# EFR32MG27C230F768IM40 register map
Vendor: Silicon Labs; Series: EFR32; File version: B
Registers are 32-bit, read-write, reset 0x0 unless marked. A register's access mark holds for its fields unless they carry their own. Offsets are from the block's base; [hi:lo] are bit positions; {n}, {i} and the like mark numbered series; 'fields as' and 'values as' point back to an identical list.

## MSC_NS — MSC_NS Registers
Base 0x50030000
Same registers: MSC_S 0x40030000
0x00 IPVERSION ro reset 0x5
  [31:0] IPVERSION — IP Version ID
0x04 READCTRL reset 0x200000
  [21:20] MODE — Read Mode
    0=WS0 (Zero wait-states inserted in fetch or read transfers); 1=WS1 (One wait-state inserted for each fetch or read transfer. See Flash Wait-States table for details); 2=WS2 (Two wait-states inserted for eatch fetch or read transfer. See Flash Wait-States table for details); 3=WS3 (Three wait-states inserted for eatch fetch or read transfer. See Flash Wait-States table for details)
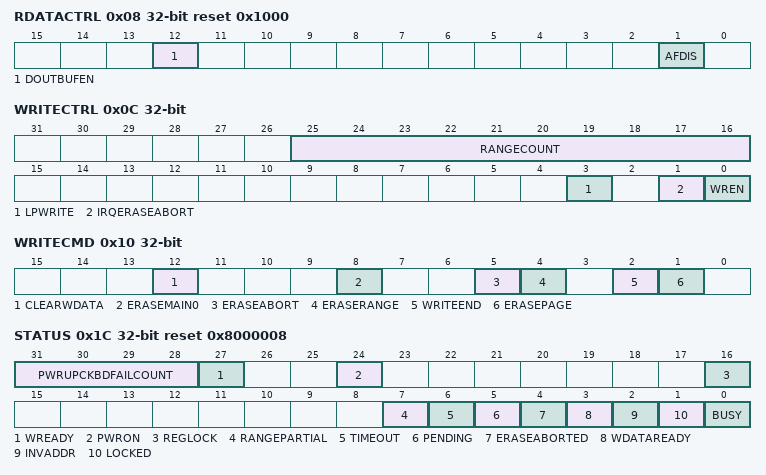
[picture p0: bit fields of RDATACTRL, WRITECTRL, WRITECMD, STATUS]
0x08 RDATACTRL reset 0x1000
  [12] DOUTBUFEN — Flash dout pipeline buffer enable
  [1] AFDIS — Automatic Invalidate Disable
0x0C WRITECTRL
  [25:16] RANGECOUNT — EraseRange Count
  [3] LPWRITE — Low-Power Write
  [1] IRQERASEABORT — Abort Page Erase on Interrupt
  [0] WREN — Enable Write/Erase Controller
0x10 WRITECMD wo
  [12] CLEARWDATA — Clear WDATA state
  [8] ERASEMAIN0 — Mass erase region 0
  [5] ERASEABORT — Abort erase sequence
  [4] ERASERANGE — Erase range of pages
  [2] WRITEEND — End Write Mode
  [1] ERASEPAGE
0x14 ADDRB
  [31:0] ADDRB — Page Erase or Write Address Buffer
0x18 WDATA
  [31:0] DATAW — Write Data
0x1C STATUS ro reset 0x8000008
  [31:28] PWRUPCKBDFAILCOUNT — Flash power up checkerboard pattern chec
  [27] WREADY — Flash Write Ready
  [24] PWRON — Flash Power On Status
  [16] REGLOCK — Register Lock Status
    0=UNLOCKED; 1=LOCKED
  [7] RANGEPARTIAL — EraseRange with skipped locked pages
  [6] TIMEOUT — Write Command Timeout
  [5] PENDING — Write Command In Queue
  [4] ERASEABORTED — Erase Operation Aborted
  [3] WDATAREADY — WDATA Write Ready
  [2] INVADDR — Invalid Write Address or Erase Page
  [1] LOCKED — Access Locked
  [0] BUSY — Erase/Write Busy
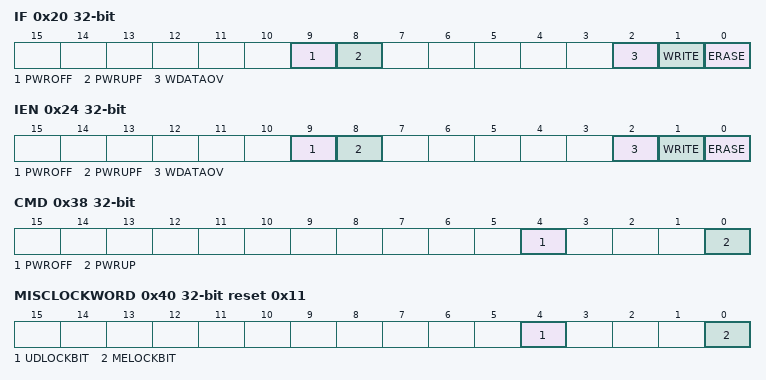
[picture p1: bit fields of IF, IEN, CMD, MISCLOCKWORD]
0x20 IF
  [9] PWROFF — Flash Power Off Sequence Complete Flag
  [8] PWRUPF — Flash Power Up Sequence Complete Flag
  [2] WDATAOV — Host write buffer overflow
  [1] WRITE — Host Write Done Interrupt Read Flag
  [0] ERASE — Host Erase Done Interrupt Read Flag
0x24 IEN
  [9] PWROFF — Flash Power Off Seq done irq enable
  [8] PWRUPF — Flash Power Up Seq done irq enable
  [2] WDATAOV — write data buffer overflow irq enable
  [1] WRITE — Write Done Interrupt enable
  [0] ERASE — Erase Done Interrupt enable
0x34 USERDATASIZE ro reset 0x4
  [5:0] USERDATASIZE
0x38 CMD wo
  [4] PWROFF — Flash power off/sleep command
  [0] PWRUP — Flash Power Up Command
0x3C LOCK wo
  [15:0] LOCKKEY — Configuration Lock
    0=LOCK; 0x1B71=UNLOCK
0x40 MISCLOCKWORD reset 0x11
  [4] UDLOCKBIT — User Data Lock
  [0] MELOCKBIT — Mass Erase Lock
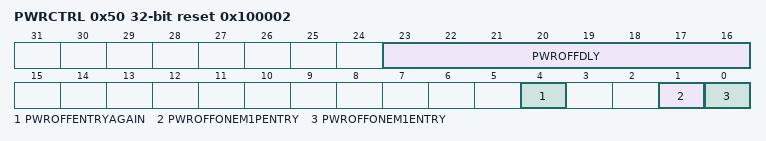
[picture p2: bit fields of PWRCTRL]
0x50 PWRCTRL reset 0x100002
  [23:16] PWROFFDLY — Power down delay
  [4] PWROFFENTRYAGAIN — POWER down flash again in EM1/EM1p
  [1] PWROFFONEM1PENTRY — Power down Flash macro when enter EM1P
  [0] PWROFFONEM1ENTRY — Power down Flash macro when enter EM1
{0x120+4i} PAGELOCK{i} (i=0..2)
  [31:0] LOCKBIT — page lock bit

## PDM_NS — PDM_NS Registers
Base 0x50098000
Same registers: PDM_S 0x40098000
0x00 IPVERSION ro
0x04 EN
  [0] EN — PDM enable
    0=DISABLE (Disable module); 1=ENABLE (Enable module)
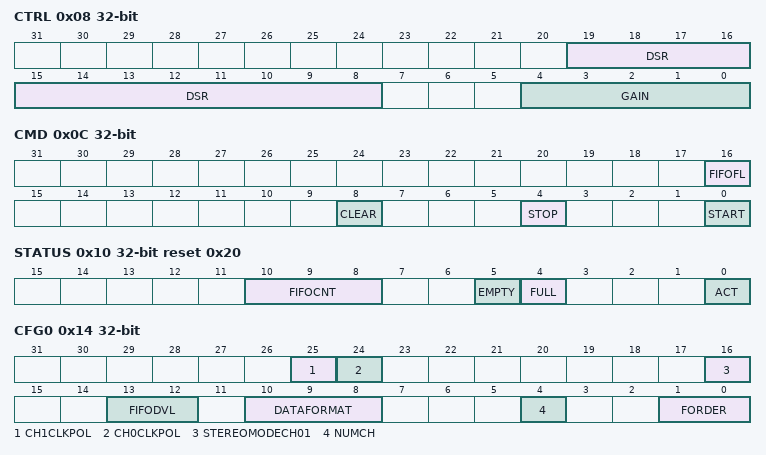
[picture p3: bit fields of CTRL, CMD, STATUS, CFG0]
0x08 CTRL
  [19:8] DSR — Down sampling rate of Decimation filter
  [4:0] GAIN — Selects Gain factor of DCF
0x0C CMD wo
  [16] FIFOFL — FIFO Flush
  [8] CLEAR — Clear DCF
  [4] STOP — Stop DCF
  [0] START — Start DCF
0x10 STATUS ro reset 0x20
  [10:8] FIFOCNT
  [5] EMPTY — FIFO EMPTY Status
  [4] FULL — FIFO FULL Status
  [0] ACT — PDM is active
0x14 CFG0
  [25] CH1CLKPOL — CH1 CLK Polarity
    0=NORMAL (Input data clocked on rising clock edge.); 1=INVERT (Input data clocked on falling clock edge.)
  [24] CH0CLKPOL — CH0 CLK Polarity
    values as CH1CLKPOL
  [16] STEREOMODECH01
    0=DISABLE (No Stereo mode.); 1=CH01ENABLE (CH0 and CH1 in Stereo mode.)
  [13:12] FIFODVL — Data Valid level in FIFO
    0=ONE (Atleast one word.); 1=TWO (Two words.); 2=THREE (Three words.); 3=FOUR (Four words.)
  [10:8] DATAFORMAT — Filter output format
    0=RIGHT16 (Right aligned 16-bit, left bits are sign extended.); 1=DOUBLE16 (Pack two 16-bit samples into one 32-bit word.); 2=RIGHT24 (Right aligned 24bit, left bits are sign extended.); 3=FULL32BIT (32 bit data.); 4=LEFT16 (Left aligned 16-bit, right bits are zeros.); 5=LEFT24 (Left aligned 24-bit, right bits are zeros.); 6=RAW32BIT (RAW 32 bit data from Integrator.)
  [4] NUMCH — Number of Channels
    0=ONE (One channel.); 1=TWO (Two channels.)
  [1:0] FORDER — Filter order
    0=SECOND (Second order filter.); 1=THIRD (Third order filter.); 2=FOURTH (Fourth order filter.); 3=FIFTH (Fifth order filter.)
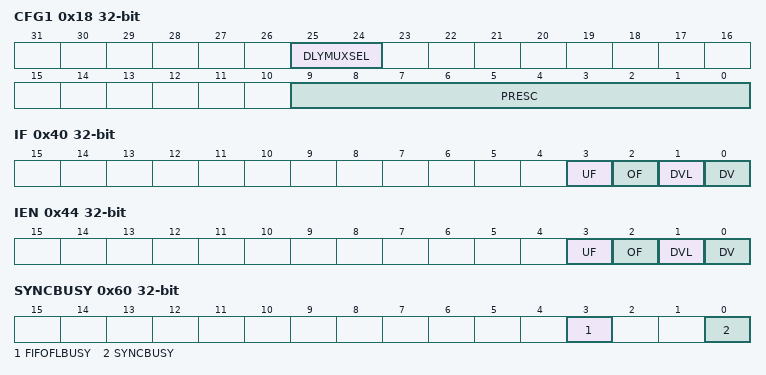
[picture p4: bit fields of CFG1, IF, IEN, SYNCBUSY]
0x18 CFG1
  [25:24] DLYMUXSEL — Data delay buffer mux selection
  [9:0] PRESC — Prescalar Setting for PDM sample
0x20 RXDATA ro
  [31:0] RXDATA — PDM received data
0x40 IF
  [3] UF — FIFO Undeflow Interrupt Flag
  [2] OF — FIFO Overflow Interrupt Flag
  [1] DVL — Data Valid Level Interrupt Flag
  [0] DV — Data Valid Interrupt Flag
0x44 IEN
  [3] UF — FIFO Undeflow Interrupt Enable
  [2] OF — FIFO Overflow Interrupt Enable
  [1] DVL — Data Valid Level Interrupt Enable
  [0] DV — Data Valid Interrupt Enable
0x60 SYNCBUSY ro
  [3] FIFOFLBUSY — FIFO Flush Sync busy
  [0] SYNCBUSY
